# bcm2835_lpa register map
Vendor: BROADCOM; Series: BCM2835; File version: A
CPU: CA72 r0p0, little endian, MPU, FPU, 2 interrupt priority bits
Registers are 32-bit, read-write, reset 0x0 unless marked. A register's access mark holds for its fields unless they carry their own. Offsets are from the block's base; [hi:lo] are bit positions; {n}, {i} and the like mark numbered series; 'fields as' and 'values as' point back to an identical list.

## USB_OTG_GLOBAL — USB on the go high speed
Base 0x20980000
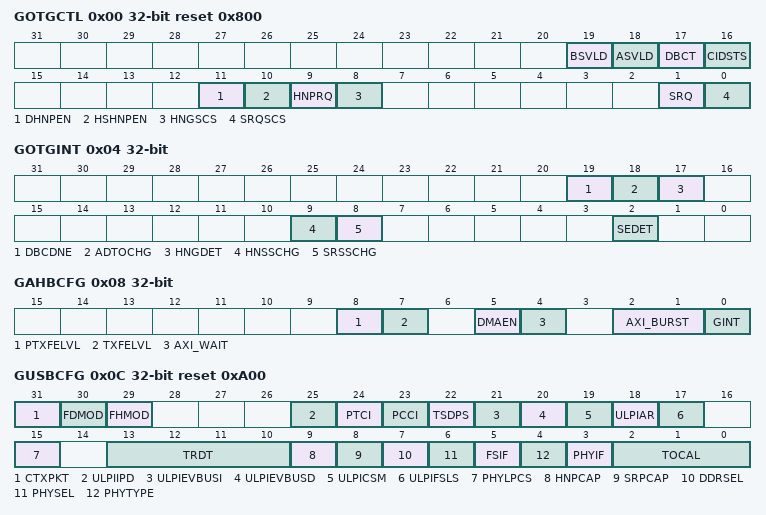
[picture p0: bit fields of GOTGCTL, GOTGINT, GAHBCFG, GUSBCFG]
0x00 GOTGCTL access per field reset 0x800 — OTG_HS control and status register
  [19] BSVLD ro — B-session valid
  [18] ASVLD ro — A-session valid
  [17] DBCT ro — Long/short debounce time
  [16] CIDSTS ro — Connector ID status
  [11] DHNPEN rw — Device HNP enabled
  [10] HSHNPEN rw — Host set HNP enable
  [9] HNPRQ rw — HNP request
  [8] HNGSCS ro — Host negotiation success
  [1] SRQ rw — Session request
  [0] SRQSCS ro — Session request success
0x04 GOTGINT — OTG_HS interrupt register
  [19] DBCDNE — Debounce done
  [18] ADTOCHG — A-device timeout change
  [17] HNGDET — Host negotiation detected
  [9] HNSSCHG — Host negotiation success status change
  [8] SRSSCHG — Session request success status change
  [2] SEDET — Session end detected
0x08 GAHBCFG — OTG_HS AHB configuration register
  [8] PTXFELVL — Periodic TxFIFO empty level
  [7] TXFELVL — TxFIFO empty level
  [5] DMAEN — DMA enable
  [4] AXI_WAIT — Wait for all AXI writes before signaling DMA
  [2:1] AXI_BURST — Maximum AXI burst length
    0=4; 1=3; 2=2; 3=1
  [0] GINT — Global interrupt mask
0x0C GUSBCFG reset 0xA00 — OTG_HS USB configuration register
  [31] CTXPKT — Corrupt Tx packet
  [30] FDMOD — Forced peripheral mode
  [29] FHMOD — Forced host mode
  [25] ULPIIPD — ULPI interface protect disable
  [24] PTCI — Indicator pass through
  [23] PCCI — Indicator complement
  [22] TSDPS — TermSel DLine pulsing selection
  [21] ULPIEVBUSI — ULPI external VBUS indicator
  [20] ULPIEVBUSD — ULPI External VBUS Drive
  [19] ULPICSM — ULPI Clock SuspendM
  [18] ULPIAR — ULPI Auto-resume
  [17] ULPIFSLS — ULPI FS/LS select
  [15] PHYLPCS — PHY Low-power clock select
  [13:10] TRDT — USB turnaround time
  [9] HNPCAP — HNP-capable
  [8] SRPCAP — SRP-capable
  [7] DDRSEL — ULPI data rate
    0=SINGLE; 1=DOUBLE
  [6] PHYSEL — Transceiver select
    0=USB20; 1=USB11
  [5] FSIF — Full speed interface
    0=6PIN; 1=3PIN
  [4] PHYTYPE
    0=UTMI; 1=ULPI
  [3] PHYIF — PHY Interface width
    0=8BIT; 1=16BIT
  [2:0] TOCAL — FS timeout calibration
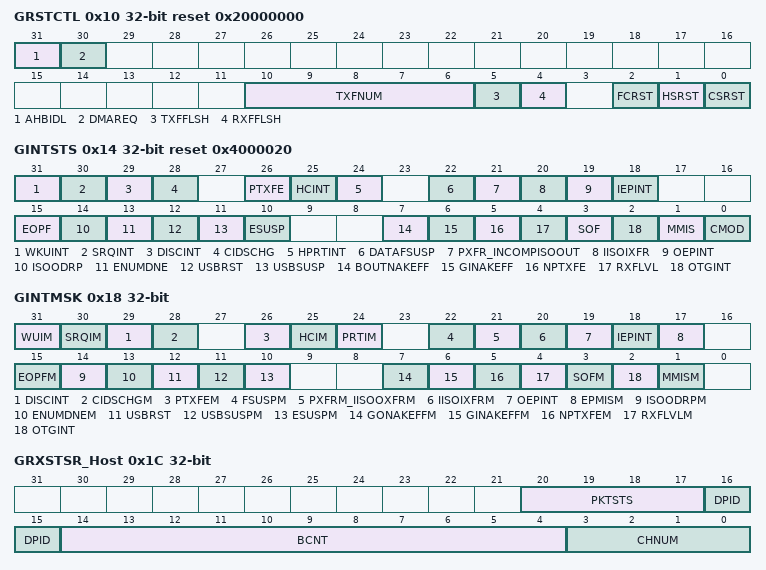
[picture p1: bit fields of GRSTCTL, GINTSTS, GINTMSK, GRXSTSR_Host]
0x10 GRSTCTL access per field reset 0x20000000 — OTG_HS reset register
  [31] AHBIDL ro — AHB master idle
  [30] DMAREQ ro — DMA request signal
  [10:6] TXFNUM rw — TxFIFO number
  [5] TXFFLSH rw — TxFIFO flush
  [4] RXFFLSH rw — RxFIFO flush
  [2] FCRST rw — Host frame counter reset
  [1] HSRST rw — HCLK soft reset
  [0] CSRST rw — Core soft reset
0x14 GINTSTS access per field reset 0x4000020 — OTG_HS core interrupt register
  [31] WKUINT rw — Resume/remote wakeup detected interrupt
  [30] SRQINT rw — Session request/new session detected interrupt
  [29] DISCINT rw — Disconnect detected interrupt
  [28] CIDSCHG rw — Connector ID status change
  [26] PTXFE ro — Periodic TxFIFO empty
  [25] HCINT ro — Host channels interrupt
  [24] HPRTINT ro — Host port interrupt
  [22] DATAFSUSP rw — Data fetch suspended
  [21] PXFR_INCOMPISOOUT rw — Incomplete periodic transfer
  [20] IISOIXFR rw — Incomplete isochronous IN transfer
  [19] OEPINT ro — OUT endpoint interrupt
  [18] IEPINT ro — IN endpoint interrupt
  [15] EOPF rw — End of periodic frame interrupt
  [14] ISOODRP rw — Isochronous OUT packet dropped interrupt
  [13] ENUMDNE rw — Enumeration done
  [12] USBRST rw — USB reset
  [11] USBSUSP rw — USB suspend
  [10] ESUSP rw — Early suspend
  [7] BOUTNAKEFF ro — Global OUT NAK effective
  [6] GINAKEFF ro — Global IN nonperiodic NAK effective
  [5] NPTXFE ro — Nonperiodic TxFIFO empty
  [4] RXFLVL ro — RxFIFO nonempty
  [3] SOF rw — Start of frame
  [2] OTGINT ro — OTG interrupt
  [1] MMIS rw — Mode mismatch interrupt
  [0] CMOD ro — Current mode of operation
0x18 GINTMSK access per field — OTG_HS interrupt mask register
  [31] WUIM rw — Resume/remote wakeup detected interrupt mask
  [30] SRQIM rw — Session request/new session detected interrupt mask
  [29] DISCINT rw — Disconnect detected interrupt mask
  [28] CIDSCHGM rw — Connector ID status change mask
  [26] PTXFEM rw — Periodic TxFIFO empty mask
  [25] HCIM rw — Host channels interrupt mask
  [24] PRTIM ro — Host port interrupt mask
  [22] FSUSPM rw — Data fetch suspended mask
  [21] PXFRM_IISOOXFRM rw — Incomplete periodic transfer mask
  [20] IISOIXFRM rw — Incomplete isochronous IN transfer mask
  [19] OEPINT rw — OUT endpoints interrupt mask
  [18] IEPINT rw — IN endpoints interrupt mask
  [17] EPMISM rw — Endpoint mismatch interrupt mask
  [15] EOPFM rw — End of periodic frame interrupt mask
  [14] ISOODRPM rw — Isochronous OUT packet dropped interrupt mask
  [13] ENUMDNEM rw — Enumeration done mask
  [12] USBRST rw — USB reset mask
  [11] USBSUSPM rw — USB suspend mask
  [10] ESUSPM rw — Early suspend mask
  [7] GONAKEFFM rw — Global OUT NAK effective mask
  [6] GINAKEFFM rw — Global nonperiodic IN NAK effective mask
  [5] NPTXFEM rw — Nonperiodic TxFIFO empty mask
  [4] RXFLVLM rw — Receive FIFO nonempty mask
  [3] SOFM rw — Start of frame mask
  [2] OTGINT rw — OTG interrupt mask
  [1] MMISM rw — Mode mismatch interrupt mask
0x1C GRXSTSR_Host ro — OTG_HS Receive status debug read register (host mode)
  [20:17] PKTSTS — Packet status
  [16:15] DPID — Data PID
  [14:4] BCNT — Byte count
  [3:0] CHNUM — Channel number
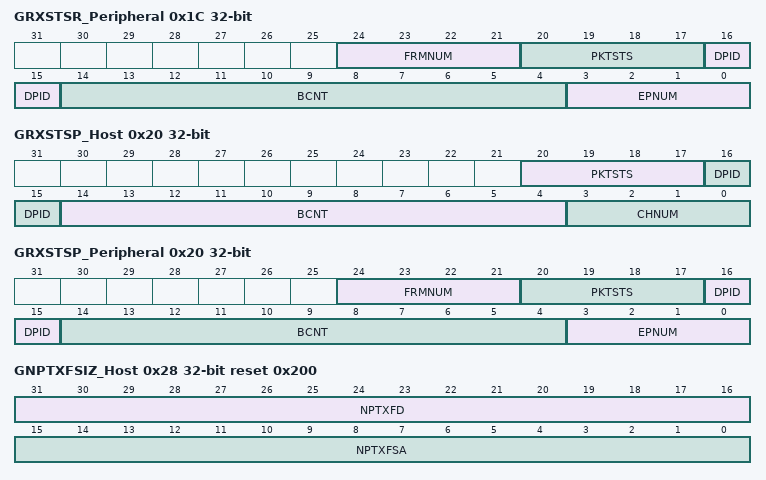
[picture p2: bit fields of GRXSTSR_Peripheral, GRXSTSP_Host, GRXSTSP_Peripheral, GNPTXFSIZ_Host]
0x1C GRXSTSR_Peripheral ro (alternate view of GRXSTSR_Host) — OTG_HS Receive status debug read register (peripheral mode mode)
  [24:21] FRMNUM — Frame number
  [20:17] PKTSTS — Packet status
  [16:15] DPID — Data PID
  [14:4] BCNT — Byte count
  [3:0] EPNUM — Endpoint number
0x20 GRXSTSP_Host ro — OTG_HS status read and pop register (host mode)
  fields as GRXSTSR_Host
0x20 GRXSTSP_Peripheral ro (alternate view of GRXSTSP_Host) — OTG_HS status read and pop register (peripheral mode)
  fields as GRXSTSR_Peripheral
0x24 GRXFSIZ reset 0x200 — OTG_HS Receive FIFO size register
  [15:0] RXFD — RxFIFO depth
0x28 GNPTXFSIZ_Host reset 0x200 — OTG_HS nonperiodic transmit FIFO size register (host mode)
  [31:16] NPTXFD — Nonperiodic TxFIFO depth
  [15:0] NPTXFSA — Nonperiodic transmit RAM start address
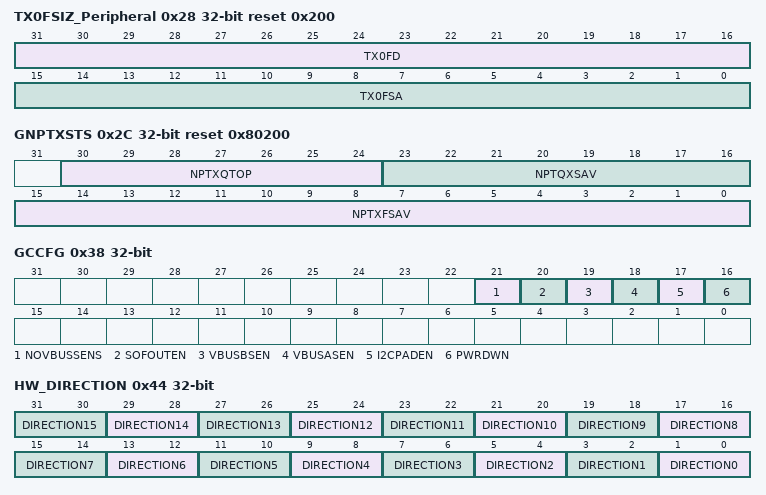
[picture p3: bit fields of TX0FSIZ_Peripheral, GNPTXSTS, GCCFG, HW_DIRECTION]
0x28 TX0FSIZ_Peripheral reset 0x200 (alternate view of GNPTXFSIZ_Host) — Endpoint 0 transmit FIFO size (peripheral mode)
  [31:16] TX0FD — Endpoint 0 TxFIFO depth
  [15:0] TX0FSA — Endpoint 0 transmit RAM start address
0x2C GNPTXSTS ro reset 0x80200 — OTG_HS nonperiodic transmit FIFO/queue status register
  [30:24] NPTXQTOP — Top of the nonperiodic transmit request queue
  [23:16] NPTQXSAV — Nonperiodic transmit request queue space available
  [15:0] NPTXFSAV — Nonperiodic TxFIFO space available
0x38 GCCFG — OTG_HS general core configuration register
  [21] NOVBUSSENS — VBUS sensing disable option
  [20] SOFOUTEN — SOF output enable
  [19] VBUSBSEN — Enable the VBUS sensing device
  [18] VBUSASEN — Enable the VBUS sensing device
  [17] I2CPADEN — Enable I2C bus connection for the external I2C PHY interface
  [16] PWRDWN — Power down
0x3C CID reset 0x1200 — OTG_HS core ID register
  [31:0] PRODUCT_ID
0x40 VID ro reset not defined — OTG_HS vendor ID register
0x44 HW_DIRECTION ro reset not defined — Direction
  [2n+1:2n] DIRECTION{n} (n=0..15) — Direction {n}
    0=BIDIR; 1=IN; 2=OUT
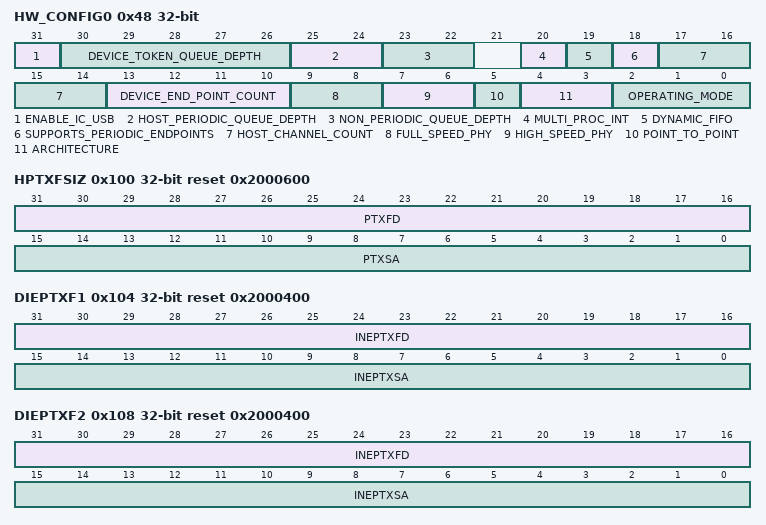
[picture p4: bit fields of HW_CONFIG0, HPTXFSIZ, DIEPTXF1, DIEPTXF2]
0x48 HW_CONFIG0 ro reset not defined — Hardware Config 0
  [31] ENABLE_IC_USB
  [30:26] DEVICE_TOKEN_QUEUE_DEPTH
  [25:24] HOST_PERIODIC_QUEUE_DEPTH
  [23:22] NON_PERIODIC_QUEUE_DEPTH
  [20] MULTI_PROC_INT
  [19] DYNAMIC_FIFO
  [18] SUPPORTS_PERIODIC_ENDPOINTS
  [17:14] HOST_CHANNEL_COUNT
  [13:10] DEVICE_END_POINT_COUNT
  [9:8] FULL_SPEED_PHY — Full Speed Physical
    0=PHY0; 1=DEDICATED; 2=PHY2; 3=PHY3
  [7:6] HIGH_SPEED_PHY — High Speed Physical
    0=NOT_SUPPORTED; 1=UTMI; 2=ULPI; 3=UTMI_ULPI
  [5] POINT_TO_POINT
  [4:3] ARCHITECTURE
    0=SLAVE_ONLY; 1=EXTERNAL_DMA; 2=INTERNAL_DMA
  [2:0] OPERATING_MODE
    0=HNP_SRP_CAPABLE; 1=SRP_ONLY_CAPABLE; 2=NO_HNP_SRP_CAPABLE; 3=SRP_CAPABLE_DEVICE; 4=NO_SRP_CAPABLE_DEVICE; 5=SRP_CAPABLE_HOST; 6=NO_SRP_CAPABLE_HOST
0x100 HPTXFSIZ reset 0x2000600 — OTG_HS Host periodic transmit FIFO size register
  [31:16] PTXFD — Host periodic TxFIFO depth
  [15:0] PTXSA — Host periodic TxFIFO start address
0x104 DIEPTXF1 reset 0x2000400 — OTG_HS device IN endpoint transmit FIFO size register
  [31:16] INEPTXFD — IN endpoint TxFIFO depth
  [15:0] INEPTXSA — IN endpoint FIFOx transmit RAM start address
0x108 DIEPTXF2 reset 0x2000400 — OTG_HS device IN endpoint transmit FIFO size register
  fields as DIEPTXF1
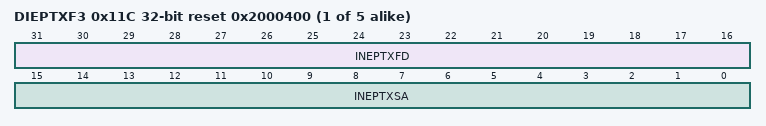
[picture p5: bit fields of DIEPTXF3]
{0x110+4i} DIEPTXF{i} reset 0x2000400 (i=3..7) — OTG_HS device IN endpoint transmit FIFO size register
  fields as DIEPTXF1
